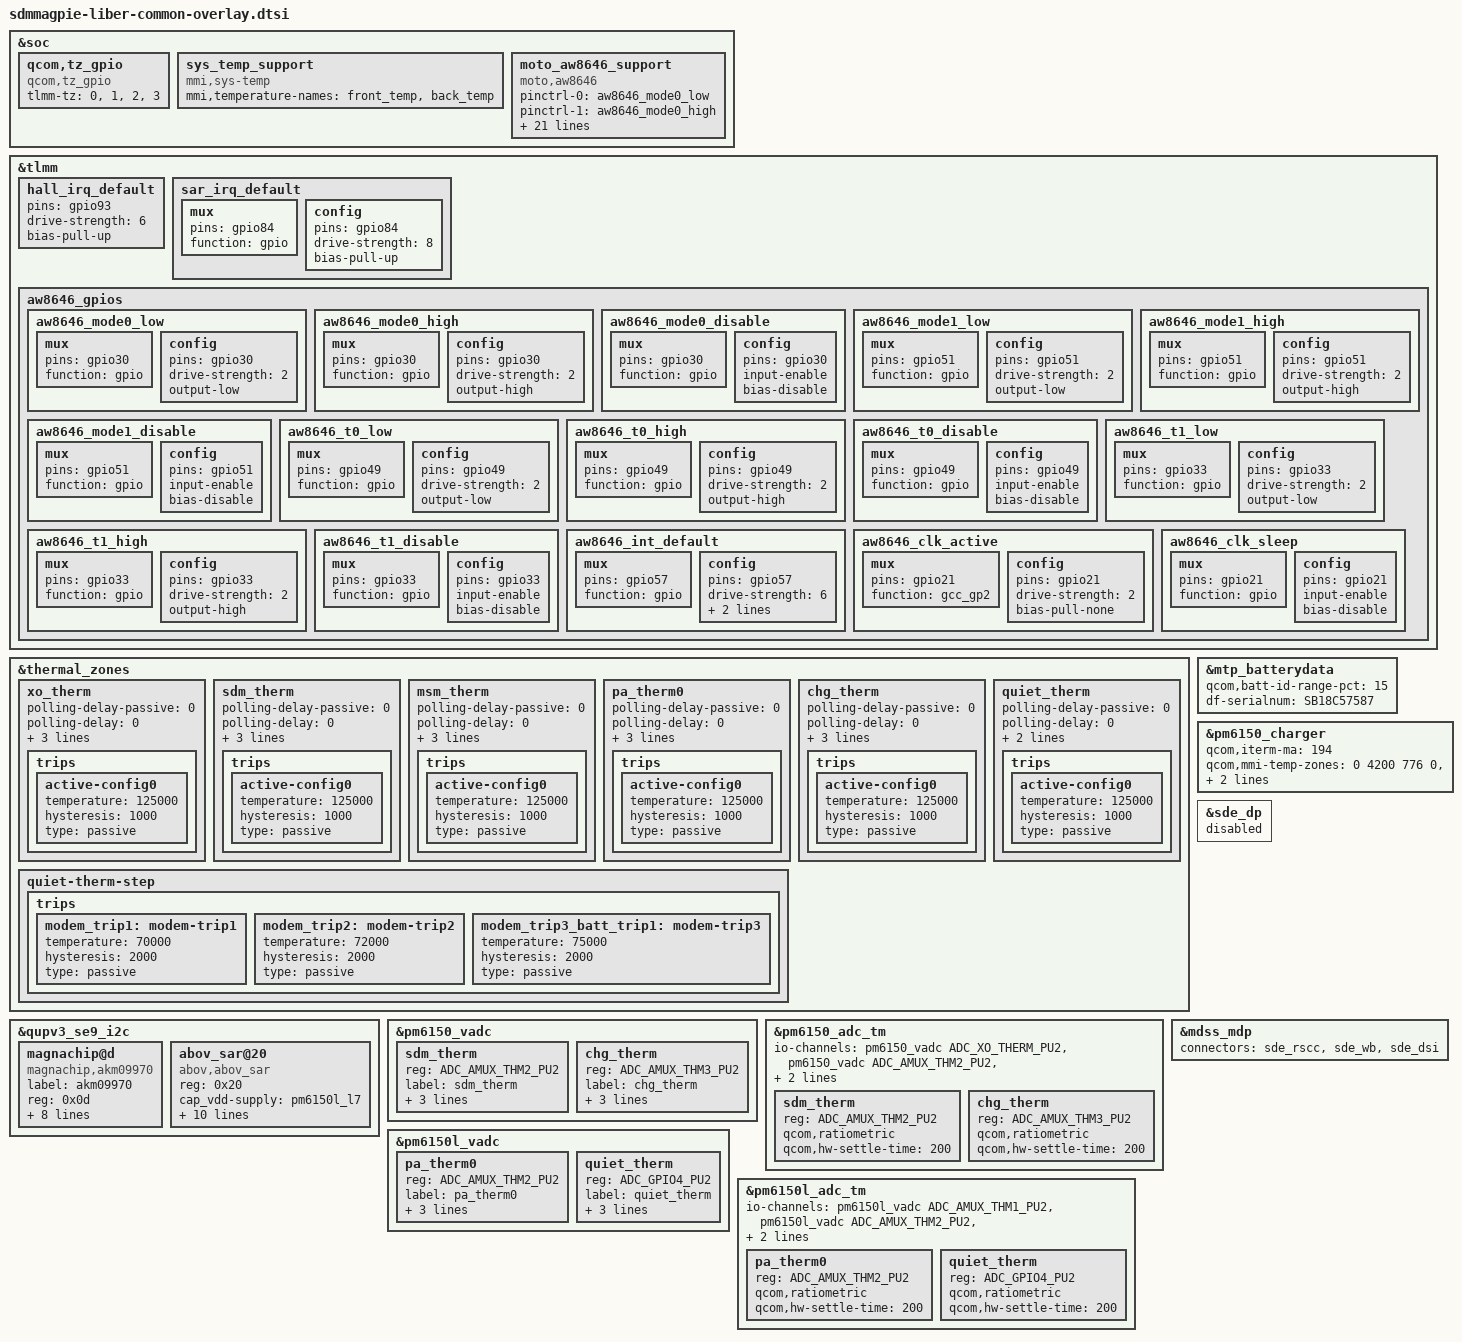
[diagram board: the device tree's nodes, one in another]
/* Copyright (c) 2018, The Linux Foundation. All rights reserved.
 *
 * This program is free software; you can redistribute it and/or modify
 * it under the terms of the GNU General Public License version 2 and
 * only version 2 as published by the Free Software Foundation.
 *
 * This program is distributed in the hope that it will be useful,
 * but WITHOUT ANY WARRANTY; without even the implied warranty of
 * MERCHANTABILITY or FITNESS FOR A PARTICULAR PURPOSE.  See the
 * GNU General Public License for more details.
 */

#include "sdmmagpie-moto-common-overlay.dtsi"
#include "sdmmagpie-liber-touch-overlay.dtsi"
#include "sdmmagpie-audio-overlay.dtsi"
#include "sdmmagpie-liber-audio-overlay.dtsi"
#include "sdmmagpie-liber-fps-overlay.dtsi"
/**
#include "sdmmagpie-camera-sensor-mot-liber-overlay.dtsi"
#include "liber-panel.dtsi"
#include "sdmmagpie-liber-charger-overlay.dtsi"
**/
#include "liber-panel.dtsi"
#include "sdmmagpie-camera-sensor-mot-liber-overlay.dtsi"

&soc {
	qcom,tz_gpio {
		compatible = "qcom,tz_gpio";
		tlmm-tz = <0>,
			<1>,
			<2>,
			<3>;
	};
};

&tlmm{
	hall_irq_default: hall_irq_default {
		pins = "gpio93";
		drive-strength = <6>;
		bias-pull-up;
	};

	sar_irq_default: sar_irq_default {
		mux {
			pins = "gpio84";
			function = "gpio";
		};
		config {
			pins = "gpio84";
			drive-strength = <8>;
			bias-pull-up;
		};
	};

	aw8646_gpios {
		aw8646_mode0_low: aw8646_mode0_low{
			mux {
				pins = "gpio30";
				function = "gpio";
			};
			config {
				pins = "gpio30";
				drive-strength = <2>; /* 2 MA */
				output-low;
			};
		};
		aw8646_mode0_high: aw8646_mode0_high{
			mux {
				pins = "gpio30";
				function = "gpio";
			};
			config {
				pins = "gpio30";
				drive-strength = <2>; /* 2 MA */
				output-high;
			};
		};
		aw8646_mode0_disable: aw8646_mode0_disable {
			mux {
				pins = "gpio30";
				function = "gpio";
			};
			config {
				pins = "gpio30";
				input-enable;
				bias-disable;
			};
		};

		aw8646_mode1_low: aw8646_mode1_low {
			mux {
				pins = "gpio51";
				function = "gpio";
			};
			config {
				pins = "gpio51";
				drive-strength = <2>; /* 2 MA */
				output-low;
			};
		};
		aw8646_mode1_high: aw8646_mode1_high {
			mux {
				pins = "gpio51";
				function = "gpio";
			};
			config {
				pins = "gpio51";
				drive-strength = <2>; /* 2 MA */
				output-high;
			};
		};
		aw8646_mode1_disable: aw8646_mode1_disable {
			mux {
				pins = "gpio51";
				function = "gpio";
			};
			config {
				pins = "gpio51";
				input-enable;
				bias-disable;
			};
		};

		aw8646_t0_low: aw8646_t0_low {
			mux {
				pins = "gpio49";
				function = "gpio";
			};
			config {
				pins = "gpio49";
				drive-strength = <2>; /* 2 MA */
				output-low;
			};
		};
		aw8646_t0_high: aw8646_t0_high {
			mux {
				pins = "gpio49";
				function = "gpio";
			};
			config {
				pins = "gpio49";
				drive-strength = <2>; /* 2 MA */
				output-high;
			};
		};
		aw8646_t0_disable: aw8646_t0_disable {
			mux {
				pins = "gpio49";
				function = "gpio";
			};
			config {
				pins = "gpio49";
				input-enable;
				bias-disable;
			};
		};

		aw8646_t1_low: aw8646_t1_low {
			mux {
				pins = "gpio33";
				function = "gpio";
			};
			config {
				pins = "gpio33";
				drive-strength = <2>; /* 2 MA */
				output-low;
			};
		};
		aw8646_t1_high: aw8646_t1_high {
			mux {
				pins = "gpio33";
				function = "gpio";
			};
			config {
				pins = "gpio33";
				drive-strength = <2>; /* 2 MA */
				output-high;
			};
		};
		aw8646_t1_disable: aw8646_t1_disable {
			mux {
				pins = "gpio33";
				function = "gpio";
			};
			config {
				pins = "gpio33";
				input-enable;
				bias-disable;
			};
		};

		aw8646_int_default: aw8646_int_default {
			mux {
				pins = "gpio57";
				function = "gpio";
			};
			config {
				pins = "gpio57";
				drive-strength = <6>;
				input-enable;
				bias-disable;
			};
		};

		aw8646_clk_active: aw8646_clk_active {
			mux {
				pins = "gpio21";
				function = "gcc_gp2";
			};
			config {
				pins = "gpio21";
				drive-strength = <2>; /* 2 MA */
				bias-pull-none;
			};
		};
		aw8646_clk_sleep: aw8646_clk_sleep{
			mux {
				pins = "gpio21";
				function = "gpio";
			};
			config {
				pins = "gpio21";
				/* drive-strength = <2>; */ /* 2 MA */
				/* bias-pull-down; */
				input-enable;
				bias-disable;
			};
		};
	};
};

&soc {
	sys_temp_support {
		compatible = "mmi,sys-temp";
		mmi,temperature-names = "front_temp",
			"back_temp";
		status = "ok";
	};

	moto_aw8646_support {
		compatible = "moto,aw8646";
		status = "ok";
		pinctrl-names = "m0_low", "m0_high", "m0_disable",
				"m1_low", "m1_high", "m1_disable",
				"t0_low", "t0_high", "t0_disable",
				"t1_low", "t1_high", "t1_disable",
				"aw8646_int_default",
				"aw8646_clk_active", "aw8646_clk_sleep";
		pinctrl-0 = <&aw8646_mode0_low>;
		pinctrl-1 = <&aw8646_mode0_high>;
		pinctrl-2 = <&aw8646_mode0_disable>;
		pinctrl-3 = <&aw8646_mode1_low>;
		pinctrl-4 = <&aw8646_mode1_high>;
		pinctrl-5 = <&aw8646_mode1_disable>;
		pinctrl-6 = <&aw8646_t0_low>;
		pinctrl-7 = <&aw8646_t0_high>;
		pinctrl-8 = <&aw8646_t0_disable>;
		pinctrl-9 = <&aw8646_t1_low>;
		pinctrl-10 = <&aw8646_t1_high>;
		pinctrl-11 = <&aw8646_t1_disable>;
		pinctrl-12 = <&aw8646_int_default>;
		pinctrl-13 = <&aw8646_clk_active>;
		pinctrl-14 = <&aw8646_clk_sleep>;
		clocks = <&clock_gcc 36>;
		clock-names = "gcc_gp2";
		vdd-supply = <&pm6150_l13>;
		interrupt-parent = <&tlmm>;
		interrupts = <57 0x2002>;
		aw8646-gpios = <52 57 21 32 30 51 29 50 49 33>;
		aw8646-gpios-cells = <10>;
		aw8646-max-freq = <250000>;
		enable-hw-clock;
	};
};

&thermal_zones {
	xo_therm {
		polling-delay-passive = <0>;
		polling-delay = <0>;
		thermal-governor = "user_space";
		thermal-sensors = <&pm6150_adc_tm ADC_XO_THERM_PU2>;
		trips {
			active-config0 {
				temperature = <125000>;
				hysteresis = <1000>;
				type = "passive";
			};
		};
	};

	sdm_therm {
		polling-delay-passive = <0>;
		polling-delay = <0>;
		thermal-governor = "user_space";
		thermal-sensors = <&pm6150_adc_tm ADC_AMUX_THM2_PU2>;
		trips {
			active-config0 {
				temperature = <125000>;
				hysteresis = <1000>;
				type = "passive";
			};
		};
	};
/*
	conn_therm {
		polling-delay-passive = <0>;
		polling-delay = <0>;
		thermal-governor = "user_space";
		thermal-sensors = <&pm6150_adc_tm ADC_AMUX_THM4_PU2>;
		trips {
			active-config0 {
				temperature = <125000>;
				hysteresis = <1000>;
				type = "passive";
			};
		};
	};
*/
	msm_therm {
		polling-delay-passive = <0>;
		polling-delay = <0>;
		thermal-governor = "user_space";
		thermal-sensors = <&pm6150_adc_tm ADC_AMUX_THM2_PU2>;
		trips {
			active-config0 {
				temperature = <125000>;
				hysteresis = <1000>;
				type = "passive";
			};
		};
	};
/*
	bob_therm {
		polling-delay-passive = <0>;
		polling-delay = <0>;
		thermal-governor = "user_space";
		thermal-sensors = <&pm6150_adc_tm ADC_AMUX_THM2_PU2>;
		trips {
			active-config0 {
				temperature = <125000>;
				hysteresis = <1000>;
				type = "passive";
			};
		};
	};
*/
	pa_therm0 {
		polling-delay-passive = <0>;
		polling-delay = <0>;
		thermal-governor = "user_space";
		thermal-sensors = <&pm6150l_adc_tm ADC_AMUX_THM2_PU2>;
		trips {
			active-config0 {
				temperature = <125000>;
				hysteresis = <1000>;
				type = "passive";
			};
		};
	};

	chg_therm {
		polling-delay-passive = <0>;
		polling-delay = <0>;
		thermal-governor = "user_space";
		thermal-sensors = <&pm6150_adc_tm ADC_AMUX_THM3_PU2>;
		trips {
			active-config0 {
				temperature = <125000>;
				hysteresis = <1000>;
				type = "passive";
			};
		};
	};

	quiet_therm {
		polling-delay-passive = <0>;
		polling-delay = <0>;
		thermal-governor = "user_space";
		thermal-sensors = <&pm6150l_adc_tm ADC_GPIO4_PU2>;
		trips {
			active-config0 {
				temperature = <125000>;
				hysteresis = <1000>;
				type = "passive";
			};
		};
	};
	quiet-therm-step {
		trips {
			modem_trip1: modem-trip1 {
				temperature = <70000>;
				hysteresis = <2000>;
				type = "passive";
			};
			modem_trip2: modem-trip2 {
				temperature = <72000>;
				hysteresis = <2000>;
				type = "passive";
			};
			modem_trip3_batt_trip1: modem-trip3 {
				temperature = <75000>;
				hysteresis = <2000>;
				type = "passive";
			};
		};
	};
};

&qupv3_se9_i2c {
    status = "ok";

    magnachip@d {
		compatible = "magnachip,akm09970";
		label = "akm09970";
		reg = <0x0d>;
		pinctrl-names = "default";
		pinctrl-0 = <&hall_irq_default>;
		interrupt-parent = <&tlmm>;
		interrupts = <93 0x2002>;
		vdd-supply = <&pm6150_l10>;
		magnachip,init-freq = <100>;
		magnachip,gpio-int = <&tlmm 93 0x2002>;
		magnachip,gpio_rst = <&tlmm 106 0>;
		magnachip,power-always-on;
		/* magnachip,use-hrtimer; */
	};

	abov_sar@20 {
		status = "okay";
		compatible = "abov,abov_sar";
		reg = <0x20>;
		cap_vdd-supply = <&pm6150l_l7>;
		interrupt-parent = <&tlmm>;
		interrupts = <84 0x2002>;
		gpios = <&tlmm 84 0x2002>;
		pinctrl-names = "default";
		pinctrl-0 = <&sar_irq_default>;
		reg_array_len = <0x03>;
		reg_array_val = <0x07 0x00 0x08 0x1B 0xFB 0x01>;
		cap,use_channel_top = <0x01>;
		cap,use_channel_bottom_left = <0x02>; /* don't use*/
		cap,use_channel_bottom_right = <0x00>;
		label = "AbovCapSense";
	};
};

&pm6150_vadc {
	sdm_therm {
                reg = <ADC_AMUX_THM2_PU2>;
                label = "sdm_therm";
                qcom,ratiometric;
                qcom,hw-settle-time = <200>;
                qcom,pre-scaling = <1 1>;
        };

	chg_therm {
                reg = <ADC_AMUX_THM3_PU2>;
                label = "chg_therm";
                qcom,ratiometric;
                qcom,hw-settle-time = <200>;
                qcom,pre-scaling = <1 1>;
        };
};

&pm6150_adc_tm {
	io-channels = <&pm6150_vadc ADC_XO_THERM_PU2>,
			<&pm6150_vadc ADC_AMUX_THM2_PU2>,
			<&pm6150_vadc ADC_AMUX_THM3_PU2>,
			<&pm6150_vadc ADC_AMUX_THM4_PU2>;
	sdm_therm {
                reg = <ADC_AMUX_THM2_PU2>;
                qcom,ratiometric;
                qcom,hw-settle-time = <200>;
        };

	chg_therm {
		reg = <ADC_AMUX_THM3_PU2>;
		qcom,ratiometric;
		qcom,hw-settle-time = <200>;
	};
};

&pm6150l_vadc {
	pa_therm0 {
		reg = <ADC_AMUX_THM2_PU2>;
		label = "pa_therm0";
		qcom,ratiometric;
		qcom,hw-settle-time = <200>;
		qcom,pre-scaling = <1 1>;
	};

	quiet_therm {
                reg = <ADC_GPIO4_PU2>;
                label = "quiet_therm";
                qcom,ratiometric;
                qcom,hw-settle-time = <200>;
                qcom,pre-scaling = <1 1>;
        };
};

&pm6150l_adc_tm {
	io-channels = <&pm6150l_vadc ADC_AMUX_THM1_PU2>,
			<&pm6150l_vadc ADC_AMUX_THM2_PU2>,
			<&pm6150l_vadc ADC_AMUX_THM3_PU2>,
			<&pm6150l_vadc ADC_GPIO4_PU2>;

	pa_therm0 {
		reg = <ADC_AMUX_THM2_PU2>;
		qcom,ratiometric;
		qcom,hw-settle-time = <200>;
	};

	quiet_therm {
                reg = <ADC_GPIO4_PU2>;
                qcom,ratiometric;
                qcom,hw-settle-time = <200>;
        };
};

&mtp_batterydata {
       qcom,batt-id-range-pct = <15>;
       df-serialnum = "SB18C57587";
       #include "qg-batterydata-kz50-scud-5000mah.dtsi"
       #include "qg-batterydata-kz50-amperex-5000mah.dtsi"
};

&pm6150_charger {
       /delete-property/qcom,support-mods;
       qcom,iterm-ma = <194>;
       qcom,mmi-temp-zones = <0 4200 776 0>,
                               <10 4200 1940 776>,
                               <15 0 1940 1940>,
                               <45 4200 3600 2500>,
                               <60 4200 1940 0>;
};

&sde_dp {
	status = "disabled";
};


&mdss_mdp {
	connectors = <&sde_rscc &sde_wb &sde_dsi>;
};

